# PSC register map
Vendor: Texas Instruments
Peripheral module from a debugger description file (folder 66AK2G0x_66AK2G1x).
Registers are 32-bit, read-only, reset 0x0 unless marked. A register's access mark holds for its fields unless they carry their own. Offsets are as the file gives them; lines under a group give offsets from that group; [hi:lo] are bit positions; {n}, {i} and the like mark numbered series; 'fields as' and 'values as' point back to an identical list; <NAME> marks a mode.

## PSC
0x00 PID reset 0x44827A00
  [31:0] REV — TI internal data. Identifies revision of peripheral.
0x120 PTCMD wo
  [31:0] GO — Power domain GO transition command. One bit per domain. Refer to, Power Domains for the power domain assignment.). Write 1 to cause the state transition interrupt generation block to evaluate the new PTNEXT and MDCTL.NEXT states as the application desired states.
0x128 PTSTAT
  [31:0] GOSTAT_X — Power domain transition status. One bit per domain. Refer to, Power Domains for the power domain assignment.
{0x200+4i} PDSTAT{i} reset 0x100 (i=0..16)
  [1:0] STATE — Power domain status. Reset value per, Power Domains.
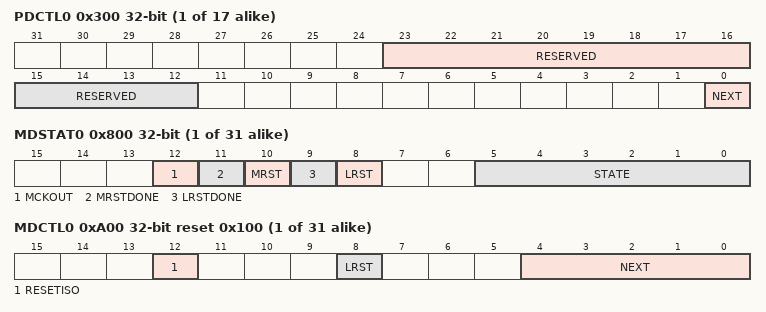
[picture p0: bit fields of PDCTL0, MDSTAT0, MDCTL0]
{0x300+4i} PDCTL{i} access per field (i=0..16)
  [23:16] RESERVED rw — Default value after reset: On domains -0x01; OFF domains -0x33. Reserved.
  [15:12] RESERVED rw — Default value after reset: On domains -0xB; OFF domains -0x8. Reserved.
  [0] NEXT rw — Default value after reset: ON domain -1; OFF domains -0. Power domain next state.
{0x800+4i} MDSTAT{i} (i=0..30)
  [12] MCKOUT — Default value after reset: Per, Clock Domains. Module clock output status. Shows status of module clock; on/off.
  [11] MRSTDONE — Module reset done. Software is responsible for checking that mode reset is done before accessing the module.
  [10] MRST — Module reset status. Reflects actual state of module reset.
  [9] LRSTDONE — Default value after reset: DSP domain -0; other domains -1. Local reset done. Software is responsible for checking that local reset is done before accessing this module.
  [8] LRST — Module local reset status.
  [5:0] STATE — Default value after reset: Per, Clock Domains. Module state status. Indicates current module status.
{0xA00+4i} MDCTL{i} access per field reset 0x100 (i=0..30)
  [12] RESETISO rw — Reset isolation.
  [8] LRST rw — Module local reset control.
  [4:0] NEXT rw — Default value after reset: Per, Clock Domains. Module next state.
